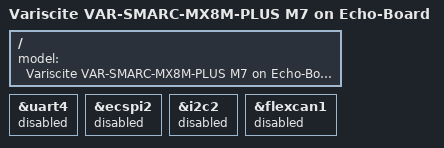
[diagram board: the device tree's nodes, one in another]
// SPDX-License-Identifier: (GPL-2.0+ OR MIT)
/*
 * Copyright 2019 NXP
 * Copyright 2026 Variscite Ltd.
 */

#include "imx8mp-var-smarc-echo.dts"
#include "imx8mp-var-common-m7.dtsi"

/ {
	model = "Variscite VAR-SMARC-MX8M-PLUS M7 on Echo-Board";
};

/*
 * ATTENTION: M7 may use IPs like below
 * ECSPI2, I2C2, UART4, PWM2, FLEXCAN1
 */

&uart4 {
	status = "disabled";
};

&ecspi2 {
	status = "disabled";
};

&i2c2 {
	status = "disabled";
};

&flexcan1 {
	status = "disabled";
};
